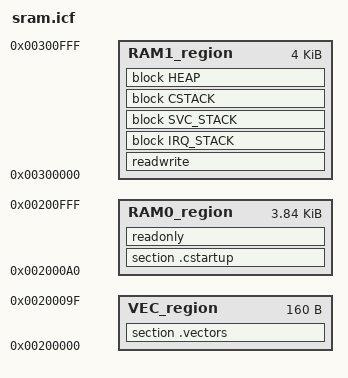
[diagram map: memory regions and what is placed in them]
/*###ICF### Section handled by ICF editor, don't touch! ****/
/*-Editor annotation file-*/
/* IcfEditorFile="$TOOLKIT_DIR$\config\ide\IcfEditor\a_v1_0.xml" */
/*-Memory Regions-*/
define symbol __ICFEDIT_region_RAM0_start__   = 0x200000;
define symbol __ICFEDIT_region_RAM0_end__     = 0x200FFF;
define symbol __ICFEDIT_region_RAM1_start__   = 0x300000;
define symbol __ICFEDIT_region_RAM1_end__     = 0x300FFF;

/*-Sizes-*/
define symbol __ICFEDIT_size_vectors__  = 0xa0;
define symbol __ICFEDIT_size_cstack__   = 0x800;
define symbol __ICFEDIT_size_svcstack__ = 0x60;
define symbol __ICFEDIT_size_irqstack__ = 0x60;
define symbol __ICFEDIT_size_heap__     = 0x0;
/*-Exports-*/
export symbol __ICFEDIT_region_RAM0_start__;
export symbol __ICFEDIT_region_RAM0_end__;
export symbol __ICFEDIT_region_RAM1_start__;
export symbol __ICFEDIT_region_RAM1_end__;
export symbol __ICFEDIT_size_vectors__;
export symbol __ICFEDIT_size_cstack__;
export symbol __ICFEDIT_size_svcstack__;
export symbol __ICFEDIT_size_irqstack__;
export symbol __ICFEDIT_size_heap__;
/**** End of ICF editor section. ###ICF###*/

define memory mem with size = 4G;
define region VEC_region = mem:[from __ICFEDIT_region_RAM0_start__ size __ICFEDIT_size_vectors__];
define region RAM0_region = mem:[from __ICFEDIT_region_RAM0_start__+__ICFEDIT_size_vectors__ to __ICFEDIT_region_RAM0_end__];
define region RAM1_region = mem:[from __ICFEDIT_region_RAM1_start__ to __ICFEDIT_region_RAM1_end__];

define block CSTACK    with alignment = 8, size = __ICFEDIT_size_cstack__   { };
define block SVC_STACK with alignment = 8, size = __ICFEDIT_size_svcstack__ { };
define block IRQ_STACK with alignment = 8, size = __ICFEDIT_size_irqstack__ { };
define block HEAP      with alignment = 8, size = __ICFEDIT_size_heap__     { };

initialize by copy { readwrite };
do not initialize  { section .noinit };

place in VEC_region { section .vectors };
place in RAM0_region { section .cstartup, readonly};
place in RAM1_region { readwrite, block IRQ_STACK, block SVC_STACK, block CSTACK, block HEAP };
